AUTOSAR XML (schema 4-2-2)
package /ComponentTypes
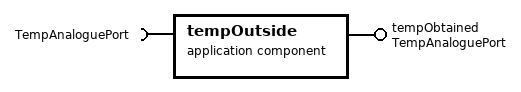
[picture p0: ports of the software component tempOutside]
  application sw component type tempOutside
    provide port tempObtained: provided-interface=TempAnaloguePort
    require port TempAnaloguePort: required-interface=TempAnaloguePort
    behavior tempOutside_InternalBehavior
  swc implementation tempOutside_Implementation: behavior=tempOutside_InternalBehavior
